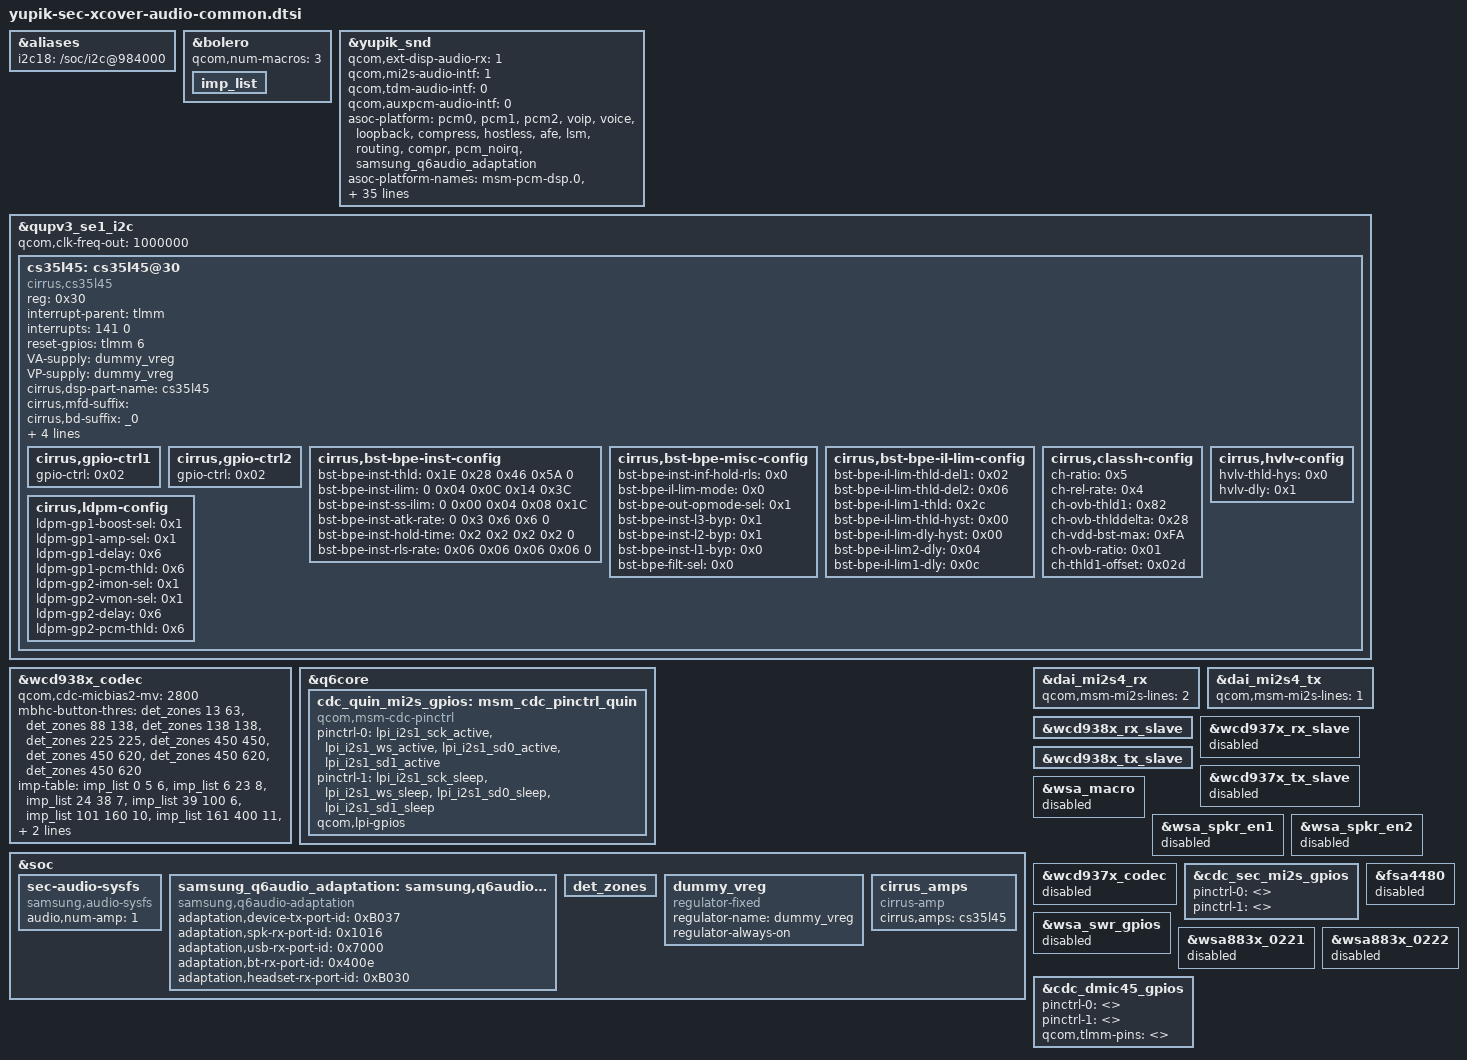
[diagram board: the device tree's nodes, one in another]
/* Copyright (c) 2019, The Linux Foundation. All rights reserved.
 *
 * This program is free software; you can redistribute it and/or modify
 * it under the terms of the GNU General Public License version 2 and
 * only version 2 as published by the Free Software Foundation.
 *
 * This program is distributed in the hope that it will be useful,
 * but WITHOUT ANY WARRANTY; without even the implied warranty of
 * MERCHANTABILITY or FITNESS FOR A PARTICULAR PURPOSE.  See the
 * GNU General Public License for more details.
 */

&aliases {
	i2c18 = "/soc/i2c@984000";
};

&bolero {
	qcom,num-macros = <3>;
	imp_list: imp_list {
		#list-imp-cells = <3>;
	};
};

&yupik_snd {
	qcom,ext-disp-audio-rx = <1>;
	qcom,mi2s-audio-intf = <1>;
	qcom,tdm-audio-intf = <0>;
	qcom,auxpcm-audio-intf = <0>;

	asoc-platform = <&pcm0>, <&pcm1>, <&pcm2>, <&voip>, <&voice>,
			<&loopback>, <&compress>, <&hostless>,
			<&afe>, <&lsm>, <&routing>, <&compr>,
			<&pcm_noirq>, <&samsung_q6audio_adaptation>;
	asoc-platform-names = "msm-pcm-dsp.0", "msm-pcm-dsp.1",
			"msm-pcm-dsp.2", "msm-voip-dsp",
			"msm-pcm-voice", "msm-pcm-loopback",
			"msm-compress-dsp", "msm-pcm-hostless",
			"msm-pcm-afe", "msm-lsm-client",
			"msm-pcm-routing", "msm-compr-dsp",
			"msm-pcm-dsp-noirq", "q6audio-adaptation";
	asoc-codec  = <&stub_codec>, <&bolero>,
		      <&wcd938x_codec>,
		      <&ext_disp_audio_codec>;
	asoc-codec-names = "msm-stub-codec.1", "bolero_codec",
			   "wcd938x_codec",
			   "msm-ext-disp-audio-codec-rx";
	qcom,audio-routing =
		"AMIC1", "Analog Mic1",
		"Analog Mic1", "MIC BIAS1",
		"AMIC2", "Analog Mic2",
		"Analog Mic2", "MIC BIAS2",
		"AMIC3", "Analog Mic3",
		"Analog Mic3", "MIC BIAS1",
		"AMIC4", "Analog Mic4",
		"Analog Mic4", "MIC BIAS3",
		"IN1_HPHL", "HPHL_OUT",
		"IN2_HPHR", "HPHR_OUT",
		"RX_TX DEC0_INP", "TX DEC0 MUX",
		"RX_TX DEC1_INP", "TX DEC1 MUX",
		"RX_TX DEC2_INP", "TX DEC2 MUX",
		"RX_TX DEC3_INP", "TX DEC3 MUX",
		"TX SWR_INPUT", "WCD_TX_OUTPUT",
		"VA SWR_INPUT", "VA_SWR_CLK",
		"VA SWR_INPUT", "WCD_TX_OUTPUT",
		"VA_AIF1 CAP", "VA_SWR_CLK",
		"VA_AIF2 CAP", "VA_SWR_CLK",
		"VA_AIF3 CAP", "VA_SWR_CLK",
		"AMP0 SPK", "Mono SPK";

	qcom,msm-mbhc-hs-mic-max-threshold-mv = <9999>;
	qcom,msm-mbhc-hs-mic-min-threshold-mv = <640>;
	qcom,cdc-dmic01-gpios = <>;
	qcom,cdc-dmic23-gpios = <>;
	qcom,cdc-dmic45-gpios = <>;
	qcom,sec-mi2s-gpios = <>;
	qcom,quin-mi2s-gpios = <&cdc_quin_mi2s_gpios>;
	qcom,wsa-max-devs = <0>;
	fsa4480-i2c-handle = <>;
	qcom,msm-mbhc-gnd-det = <1>;
	qcom,codec-conf = <0x51>;   /* CS35L45 mono */
};

&qupv3_se1_i2c {
	qcom,clk-freq-out = <1000000>;
	status = "ok";

	cs35l45: cs35l45@30 {
		#sound-dai-cells = <1>;
		compatible = "cirrus,cs35l45";
		reg = <0x30>;
		interrupt-parent = <&tlmm>;
		interrupts = <141 0>;
		reset-gpios = <&tlmm 6 0>;
		VA-supply = <&dummy_vreg>;
		VP-supply = <&dummy_vreg>;

		cirrus,dsp-part-name = "cs35l45";
		cirrus,mfd-suffix = "";
		cirrus,bd-suffix = "_0";
		cirrus,asp-sdout-hiz-ctrl = <0x3>;
		cirrus,pll-auto-en;

		pinctrl-names = "default";
		pinctrl-0 = <&cs35l45_gpio_default>;

		cirrus,perform_vimon_cal;

		cirrus,gpio-ctrl1 {
			gpio-ctrl = <0x02>;
		};

		cirrus,gpio-ctrl2 {
			gpio-ctrl = <0x02>;
		};

		cirrus,bst-bpe-inst-config {
			bst-bpe-inst-thld = <0x1E 0x28 0x46 0x5A 0>;
			bst-bpe-inst-ilim = <0 0x04 0x0C 0x14 0x3C>;
			bst-bpe-inst-ss-ilim = <0 0x00 0x04 0x08 0x1C>;
			bst-bpe-inst-atk-rate = <0 0x3 0x6 0x6 0>;
			bst-bpe-inst-hold-time = <0x2 0x2 0x2 0x2 0>;
			bst-bpe-inst-rls-rate = <0x06 0x06 0x06 0x06 0>;
		};

		cirrus,bst-bpe-misc-config {
			bst-bpe-inst-inf-hold-rls = <0x0>;
			bst-bpe-il-lim-mode = <0x0>;
			bst-bpe-out-opmode-sel = <0x1>;
			bst-bpe-inst-l3-byp = <0x1>;
			bst-bpe-inst-l2-byp = <0x1>;
			bst-bpe-inst-l1-byp = <0x0>;
			bst-bpe-filt-sel = <0x0>;
		};

		cirrus,bst-bpe-il-lim-config {
			bst-bpe-il-lim-thld-del1 = <0x02>;
			bst-bpe-il-lim-thld-del2 = <0x06>;
			bst-bpe-il-lim1-thld = <0x2c>;
			bst-bpe-il-lim-thld-hyst = <0x00>;
			bst-bpe-il-lim-dly-hyst = <0x00>;
			bst-bpe-il-lim2-dly = <0x04>;
			bst-bpe-il-lim1-dly = <0x0c>;
		};

		cirrus,classh-config {
			ch-ratio = <0x5>;
			ch-rel-rate = <0x4>;
			ch-ovb-thld1 = <0x82>;
			ch-ovb-thlddelta = <0x28>;
			ch-vdd-bst-max = <0xFA>;
			ch-ovb-ratio = <0x01>;
			ch-thld1-offset = <0x02d>;
		};

		cirrus,hvlv-config {
			hvlv-thld-hys = <0x0>;
			hvlv-dly = <0x1>;
		};

		cirrus,ldpm-config { 
			ldpm-gp1-boost-sel = <0x1>;
			ldpm-gp1-amp-sel = <0x1>;
			ldpm-gp1-delay = <0x6>;
			ldpm-gp1-pcm-thld = <0x6>;
			ldpm-gp2-imon-sel = <0x1>;
			ldpm-gp2-vmon-sel = <0x1>;
			ldpm-gp2-delay = <0x6>;
			ldpm-gp2-pcm-thld = <0x6>;
		};
	};
};

&wcd938x_codec {
	status = "ok";
	qcom,cdc-micbias2-mv = <2800>;
	mbhc-button-thres = <&det_zones 13 63>,
		 <&det_zones 88 138>,
		 <&det_zones 138 138>,
		 <&det_zones 225 225>,
		 <&det_zones 450 450>,
		 <&det_zones 450 620>,
		 <&det_zones 450 620>,
		 <&det_zones 450 620>;
	imp-table = <&imp_list 0 5 6>,
			 <&imp_list 6 23 8>,
			 <&imp_list 24 38 7>,
			 <&imp_list 39 100 6>,
			 <&imp_list 101 160 10>,
			 <&imp_list 161 400 11>,
			 <&imp_list 401 2000 11>,
			 <&imp_list 2001 0x7fffffff 6>;
};

&q6core {
	cdc_quin_mi2s_gpios: msm_cdc_pinctrl_quin {
		compatible = "qcom,msm-cdc-pinctrl";
		pinctrl-names = "aud_active", "aud_sleep";
		pinctrl-0 = <&lpi_i2s1_sck_active &lpi_i2s1_ws_active
				 &lpi_i2s1_sd0_active &lpi_i2s1_sd1_active>;
		pinctrl-1 = <&lpi_i2s1_sck_sleep &lpi_i2s1_ws_sleep
				 &lpi_i2s1_sd0_sleep &lpi_i2s1_sd1_sleep>;
		qcom,lpi-gpios;
		#gpio-cells = <0>;
	};
};

&soc {
	sec-audio-sysfs {
		compatible = "samsung,audio-sysfs";
		status = "okay";
		audio,num-amp = <1>;
	};

	samsung_q6audio_adaptation: samsung,q6audio-adaptation {
		compatible = "samsung,q6audio-adaptation";
		adaptation,device-tx-port-id = <0xB037>;
		adaptation,spk-rx-port-id = <0x1016>;
		adaptation,usb-rx-port-id = <0x7000>;
		adaptation,bt-rx-port-id = <0x400e>;
		adaptation,headset-rx-port-id = <0xB030>;
	};

	det_zones: det_zones {
		#list-det-cells = <2>;
	};

	dummy_vreg: dummy_vreg {
		compatible = "regulator-fixed";
		status = "ok";
		regulator-name = "dummy_vreg";
		regulator-always-on;
	};

	cirrus_amps {
		compatible = "cirrus-amp";
		cirrus,amps = <&cs35l45>;
	};
};

&dai_mi2s4_rx {
	qcom,msm-mi2s-lines = <2>;
};

&dai_mi2s4_tx {
	qcom,msm-mi2s-lines = <1>;
};

&wcd938x_rx_slave {
	status = "okay";
};

&wcd937x_rx_slave {
	status = "disabled";
};

&wcd938x_tx_slave {
	status = "okay";
};

&wcd937x_tx_slave {
	status = "disabled";
};

&wsa_macro {
	status = "disabled";
};

&wsa_spkr_en1 {
	status = "disabled";
};

&wsa_spkr_en2 {
	status = "disabled";
};

&wcd937x_codec {
	status = "disabled";
};

&cdc_sec_mi2s_gpios {
	pinctrl-0 = <>;
	pinctrl-1 = <>;
};

&fsa4480 {
	status = "disabled";
};

&wsa_swr_gpios {
	status = "disabled";
};

&wsa883x_0221 {
	status = "disabled";
};

&wsa883x_0222 {
	status = "disabled";
};

&cdc_dmic45_gpios {
	pinctrl-0 = <>;
	pinctrl-1 = <>;
	qcom,tlmm-pins = <>;
};
